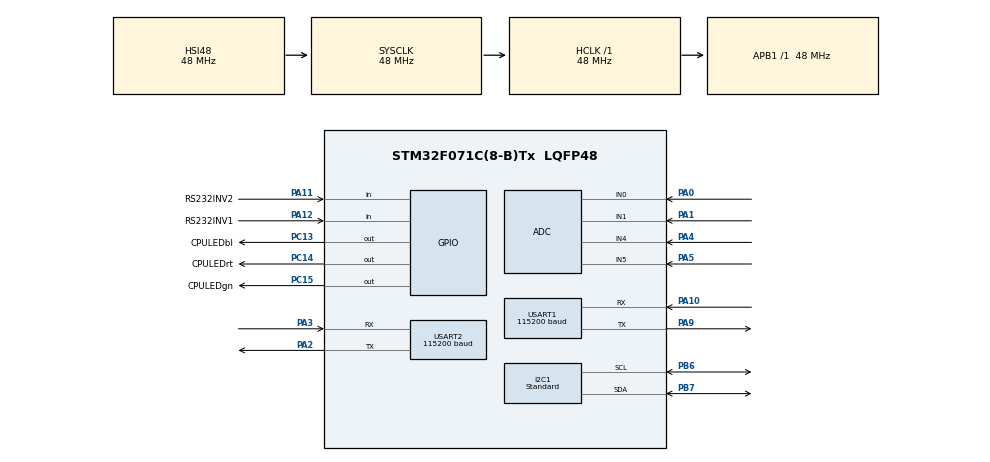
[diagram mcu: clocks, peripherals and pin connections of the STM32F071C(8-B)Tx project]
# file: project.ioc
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ADC.ClockPrescaler=ADC_CLOCK_SYNC_PCLK_DIV4
ADC.ContinuousConvMode=DISABLE
ADC.DMAContinuousRequests=ENABLE
ADC.DataAlign=ADC_DATAALIGN_RIGHT
ADC.DiscontinuousConvMode=DISABLE
ADC.EOCSelection=ADC_EOC_SEQ_CONV
ADC.Overrun=ADC_OVR_DATA_PRESERVED
ADC.SamplingTime=ADC_SAMPLETIME_13CYCLES_5
Dma.ADC.0.Direction=DMA_PERIPH_TO_MEMORY
Dma.ADC.0.Instance=DMA1_Channel1
Dma.ADC.0.MemDataAlignment=DMA_MDATAALIGN_WORD
Dma.ADC.0.MemInc=DMA_MINC_ENABLE
Dma.ADC.0.Mode=DMA_CIRCULAR
Dma.ADC.0.PeriphDataAlignment=DMA_PDATAALIGN_WORD
Dma.ADC.0.PeriphInc=DMA_PINC_DISABLE
Dma.ADC.0.Priority=DMA_PRIORITY_LOW
Dma.Request0=ADC
Dma.Request1=USART1_RX
Dma.Request2=USART1_TX
Dma.Request3=USART2_RX
Dma.Request4=USART2_TX
Dma.USART1_RX.1.Direction=DMA_PERIPH_TO_MEMORY
Dma.USART1_RX.1.Instance=DMA1_Channel3
Dma.USART1_RX.1.MemDataAlignment=DMA_MDATAALIGN_BYTE
Dma.USART1_RX.1.MemInc=DMA_MINC_ENABLE
Dma.USART1_RX.1.Mode=DMA_CIRCULAR
Dma.USART1_RX.1.PeriphDataAlignment=DMA_PDATAALIGN_BYTE
Dma.USART1_RX.1.PeriphInc=DMA_PINC_DISABLE
Dma.USART1_RX.1.Priority=DMA_PRIORITY_VERY_HIGH
Dma.USART1_TX.2.Direction=DMA_MEMORY_TO_PERIPH
Dma.USART1_TX.2.Instance=DMA1_Channel2
Dma.USART1_TX.2.MemDataAlignment=DMA_MDATAALIGN_BYTE
Dma.USART1_TX.2.MemInc=DMA_MINC_ENABLE
Dma.USART1_TX.2.Mode=DMA_CIRCULAR
Dma.USART1_TX.2.PeriphDataAlignment=DMA_PDATAALIGN_BYTE
Dma.USART1_TX.2.PeriphInc=DMA_PINC_DISABLE
Dma.USART1_TX.2.Priority=DMA_PRIORITY_VERY_HIGH
Dma.USART2_RX.3.Direction=DMA_PERIPH_TO_MEMORY
Dma.USART2_RX.3.Instance=DMA1_Channel5
Dma.USART2_RX.3.MemDataAlignment=DMA_MDATAALIGN_BYTE
Dma.USART2_RX.3.MemInc=DMA_MINC_ENABLE
Dma.USART2_RX.3.Mode=DMA_CIRCULAR
Dma.USART2_RX.3.PeriphDataAlignment=DMA_PDATAALIGN_BYTE
Dma.USART2_RX.3.PeriphInc=DMA_PINC_DISABLE
Dma.USART2_RX.3.Priority=DMA_PRIORITY_VERY_HIGH
Dma.USART2_TX.4.Direction=DMA_MEMORY_TO_PERIPH
Dma.USART2_TX.4.Instance=DMA1_Channel4
Dma.USART2_TX.4.MemDataAlignment=DMA_MDATAALIGN_BYTE
Dma.USART2_TX.4.MemInc=DMA_MINC_ENABLE
Dma.USART2_TX.4.Mode=DMA_CIRCULAR
Dma.USART2_TX.4.PeriphDataAlignment=DMA_PDATAALIGN_BYTE
Dma.USART2_TX.4.PeriphInc=DMA_PINC_DISABLE
Dma.USART2_TX.4.Priority=DMA_PRIORITY_VERY_HIGH
I2C1.I2C_Speed_Mode=I2C_Standard
Mcu.Family=STM32F0
Mcu.Name=STM32F071C(8-B)Tx
Mcu.Package=LQFP48
NVIC.DMA1_Channel1_IRQn=true\:0\:0\:false\:false\:true\:false\:true
NVIC.DMA1_Channel2_3_IRQn=true\:0\:0\:false\:false\:true\:false\:true
NVIC.DMA1_Channel4_5_6_7_IRQn=true\:0\:0\:false\:false\:true\:false\:true
NVIC.TIM3_IRQn=true\:0\:0\:false\:false\:true\:true\:true
NVIC.TIM7_IRQn=true\:0\:0\:false\:false\:true\:true\:true
NVIC.USART1_IRQn=true\:1\:0\:true\:false\:true\:true\:true
NVIC.USART2_IRQn=true\:1\:0\:true\:false\:true\:true\:true
PA0.Mode=IN0
PA0.Signal=ADC_IN0
PA1.Mode=IN1
PA1.Signal=ADC_IN1
PA10.Mode=Asynchronous
PA10.Signal=USART1_RX
PA11.GPIO_Label=RS232INV2
PA11.Signal=GPIO_Input
PA12.GPIO_Label=RS232INV1
PA12.Signal=GPIO_Input
PA15.Signal=SPI1_NSS
PA2.Mode=Asynchronous
PA2.Signal=USART2_TX
PA3.Mode=Asynchronous
PA3.Signal=USART2_RX
PA4.GPIO_PuPd=GPIO_NOPULL
PA4.Mode=IN4
PA4.Signal=ADC_IN4
PA5.Mode=IN5
PA5.Signal=ADC_IN5
PA6.Signal=SPI1_MISO
PA7.Signal=SPI1_MOSI
PA9.Mode=Asynchronous
PA9.Signal=USART1_TX
PB3.Signal=SPI1_SCK
PB6.Mode=I2C
PB6.Signal=I2C1_SCL
PB7.Mode=I2C
PB7.Signal=I2C1_SDA
PC13.GPIO_Label=CPULEDbl
PC13.Signal=GPIO_Output
PC14-OSC32_IN.GPIO_Label=CPULEDrt
PC14-OSC32_IN.Signal=GPIO_Output
PC15-OSC32_OUT.GPIO_Label=CPULEDgn
PC15-OSC32_OUT.Signal=GPIO_Output
ProjectManager.HeapSize=0x200
ProjectManager.StackSize=0x400
ProjectManager.TargetToolchain=Makefile
RCC.AHBFreq_Value=48000000
RCC.APB1Freq_Value=48000000
RCC.APB1TimFreq_Value=48000000
RCC.HCLKFreq_Value=48000000
RCC.SYSCLKFreq_VALUE=48000000
RCC.SYSCLKSource=RCC_SYSCLKSOURCE_HSI48
TIM3.Period=1000-1
TIM3.Prescaler=48
TIM7.Period=65536-1
TIM7.Prescaler=48-1
USART1.BaudRate=115200
USART1.VirtualMode-Asynchronous=VM_ASYNC
USART2.BaudRate=115200
USART2.VirtualMode-Asynchronous=VM_ASYNC
VP_TIM3_VS_ClockSourceINT.Mode=Internal
VP_TIM7_VS_ClockSourceINT.Mode=Enable_Timer
board=custom

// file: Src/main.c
/* USER CODE BEGIN Header */
/**
  ******************************************************************************
  * @file           : main.c
  * @brief          : Main program body
  ******************************************************************************
  * @attention
  *
  * <h2><center>&copy; Copyright (c) 2021 STMicroelectronics.
  * All rights reserved.</center></h2>
  *
  * This software component is licensed by ST under BSD 3-Clause license,
  * the "License"; You may not use this file except in compliance with the
  * License. You may obtain a copy of the License at:
  *                        opensource.org/licenses/BSD-3-Clause
  *
  ******************************************************************************
  */
/* USER CODE END Header */

#include "main.h"
#include "adc.h"
#include "dma.h"
#include "i2c.h"
#include "tim.h"
#include "usart.h"
#include "gpio.h"

/* USER CODE BEGIN Includes */
#include <string.h>
/* USER CODE END Includes */

void SystemClock_Config(void);

/* USER CODE BEGIN 0 */
char *message = "Hello World!";
/* USER CODE END 0 */

int main(void)
{

  /* MCU Configuration--------------------------------------------------------*/

  /* Reset of all peripherals, Initializes the Flash interface and the Systick. */
  HAL_Init();

  /* Configure the system clock */
  SystemClock_Config();

  /* Initialize all configured peripherals */
  MX_GPIO_Init();
  MX_DMA_Init();
  MX_ADC_Init();
  MX_I2C1_Init();
  MX_USART1_UART_Init();
  MX_USART2_UART_Init();
  MX_TIM3_Init();
  MX_TIM7_Init();

  /* Infinite loop */
  while (1)
  {

    /* USER CODE BEGIN 3 */

    /*Blinky yo*/
    HAL_GPIO_TogglePin(GPIOC, GPIO_PIN_13);
    HAL_Delay(500);
    /*USART*/
    HAL_UART_Transmit(&huart1, (uint8_t*)message, strlen(message), 100);

  }
  /* USER CODE END 3 */
}

void SystemClock_Config(void)
{
  RCC_OscInitTypeDef RCC_OscInitStruct = {0};
  RCC_ClkInitTypeDef RCC_ClkInitStruct = {0};
  RCC_PeriphCLKInitTypeDef PeriphClkInit = {0};

  /** Initializes the CPU, AHB and APB busses clocks
  */
  RCC_OscInitStruct.OscillatorType = RCC_OSCILLATORTYPE_HSI|RCC_OSCILLATORTYPE_HSI48;
  RCC_OscInitStruct.HSIState = RCC_HSI_ON;
  RCC_OscInitStruct.HSI48State = RCC_HSI48_ON;
  RCC_OscInitStruct.HSICalibrationValue = RCC_HSICALIBRATION_DEFAULT;
  RCC_OscInitStruct.PLL.PLLState = RCC_PLL_NONE;
  if (HAL_RCC_OscConfig(&RCC_OscInitStruct) != HAL_OK)
  {
    Error_Handler();
  }
  /** Initializes the CPU, AHB and APB busses clocks
  */
  RCC_ClkInitStruct.ClockType = RCC_CLOCKTYPE_HCLK|RCC_CLOCKTYPE_SYSCLK
                              |RCC_CLOCKTYPE_PCLK1;
  RCC_ClkInitStruct.SYSCLKSource = RCC_SYSCLKSOURCE_HSI48;
  RCC_ClkInitStruct.AHBCLKDivider = RCC_SYSCLK_DIV1;
  RCC_ClkInitStruct.APB1CLKDivider = RCC_HCLK_DIV1;

  if (HAL_RCC_ClockConfig(&RCC_ClkInitStruct, FLASH_LATENCY_1) != HAL_OK)
  {
    Error_Handler();
  }
  PeriphClkInit.PeriphClockSelection = RCC_PERIPHCLK_USART1|RCC_PERIPHCLK_USART2
                              |RCC_PERIPHCLK_I2C1;
  PeriphClkInit.Usart1ClockSelection = RCC_USART1CLKSOURCE_PCLK1;
  PeriphClkInit.Usart2ClockSelection = RCC_USART2CLKSOURCE_PCLK1;
  PeriphClkInit.I2c1ClockSelection = RCC_I2C1CLKSOURCE_HSI;
  if (HAL_RCCEx_PeriphCLKConfig(&PeriphClkInit) != HAL_OK)
  {
    Error_Handler();
  }
}

void Error_Handler(void)
{
}

/************************ (C) COPYRIGHT STMicroelectronics *****END OF FILE****/
